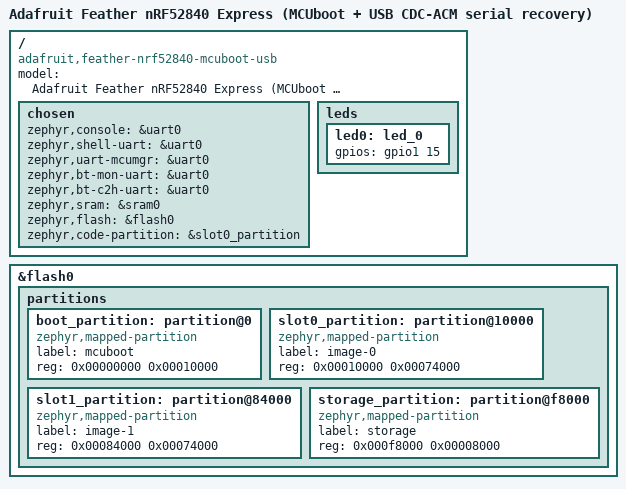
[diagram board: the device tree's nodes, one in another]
/*
 * Copyright (c) 2020 Tobias Svehagen
 * Copyright (c) 2024 Jacob Winther
 *
 * SPDX-License-Identifier: Apache-2.0
 */

/dts-v1/;
#include "adafruit_feather_nrf52840_mcuboot_usb_common.dtsi"

/ {
	model = "Adafruit Feather nRF52840 Express (MCUboot + USB CDC-ACM serial recovery)";
	compatible = "adafruit,feather-nrf52840-mcuboot-usb";

	chosen {
		zephyr,console = &uart0;
		zephyr,shell-uart = &uart0;
		zephyr,uart-mcumgr = &uart0;
		zephyr,bt-mon-uart = &uart0;
		zephyr,bt-c2h-uart = &uart0;
		zephyr,sram = &sram0;
		zephyr,flash = &flash0;
		zephyr,code-partition = &slot0_partition;
	};

	leds {
		led0: led_0 {
			gpios = <&gpio1 15 0>;
		};
	};
};

/*
 * Corrected partition table: upstream's stock 48 KB boot_partition (see
 * <nordic/nrf52840_partition.dtsi>) doesn't fit MCUboot once the USB CDC-ACM
 * serial-recovery stack and ECDSA-P256 signing are linked in -- measured
 * overflow during hardware bring-up was ~12 KB even with ECDSA-P256 (much
 * smaller than the default RSA-2048). A 60 KB boot_partition (matching the
 * ESP32-family variants' own convention) links with only 380 bytes to spare,
 * which is too thin a margin to be worth saving 4 KB over -- grown to 64 KB
 * instead, with 8 KB taken from each of the two 472 KB app slots (now 464 KB
 * each). storage_partition is untouched. No scratch_partition -- swap_method
 * offset/move don't need one, and scratch isn't used by this board's default
 * OTA config.
 */
&flash0 {
	partitions {
		ranges;
		#address-cells = <1>;
		#size-cells = <1>;

		boot_partition: partition@0 {
			compatible = "zephyr,mapped-partition";
			label = "mcuboot";
			reg = <0x00000000 0x00010000>;
		};

		slot0_partition: partition@10000 {
			compatible = "zephyr,mapped-partition";
			label = "image-0";
			reg = <0x00010000 0x00074000>;
		};

		slot1_partition: partition@84000 {
			compatible = "zephyr,mapped-partition";
			label = "image-1";
			reg = <0x00084000 0x00074000>;
		};

		/*
		 * Storage partition will be used by FCB/LittleFS/NVS
		 * if enabled. Unchanged from upstream's stock layout.
		 */
		storage_partition: partition@f8000 {
			compatible = "zephyr,mapped-partition";
			label = "storage";
			reg = <0x000f8000 0x00008000>;
		};
	};
};
